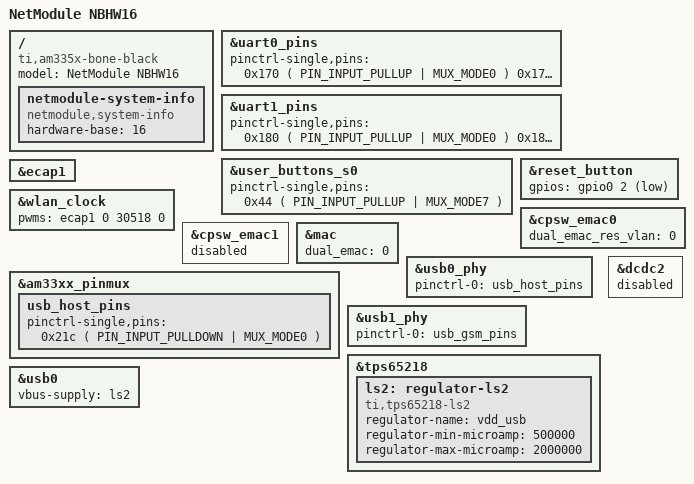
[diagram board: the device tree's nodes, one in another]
/*
 * Copyright (C) 2012 Texas Instruments Incorporated - http://www.ti.com/
 *
 * This program is free software; you can redistribute it and/or modify
 * it under the terms of the GNU General Public License version 2 as
 * published by the Free Software Foundation.
 */
/dts-v1/;

#include "am33xx.dtsi"
#include "am335x-nbhw-common.dtsi"

/ {
	model = "NetModule NBHW16";
	compatible = "ti,am335x-bone-black", "ti,am335x-bone", "ti,am33xx";

	netmodule-system-info {
		compatible = "netmodule,system-info";
		hardware-base = <16>;
	};
};

&uart0_pins {
	pinctrl-single,pins = <
		0x170 ( PIN_INPUT_PULLUP | MUX_MODE0 ) /* (E15) uart0_rxd.uart0_rxd */
		0x174 ( PIN_OUTPUT_PULLUP | MUX_MODE0 ) /* (E16) uart0_txd.uart0_txd */
		0x168 ( PIN_OUTPUT_PULLUP | MUX_MODE0 ) /* (E18) uart0_ctsn.uart0_ctsn */
		0x16C ( PIN_OUTPUT_PULLUP | MUX_MODE0 ) /* (E17) uart0_rtsn.uart0_rtsn */
	>;
};

&uart1_pins {
	pinctrl-single,pins = <
		0x180 ( PIN_INPUT_PULLUP | MUX_MODE0 ) /* (D16) uart1_rxd.uart1_rxd */
		0x184 ( PIN_OUTPUT_PULLUP | MUX_MODE0 ) /* (D15) uart1_txd.uart1_txd */
	>;
};

&user_buttons_s0 {
		pinctrl-single,pins = <
			0x44 ( PIN_INPUT_PULLUP | MUX_MODE7 ) /* (A17) gpmc_a1.gpio0[2] */ /* BUTTON */
		>;
};

&reset_button {
	gpios = <&gpio0 2 GPIO_ACTIVE_LOW>;
};

&ecap1 {
	status = "okay";
};

&wlan_clock {
	pwms = <&ecap1 0 30518 0>;
};

&cpsw_emac0 {
	dual_emac_res_vlan = <0>;
};

// V2 only has one mac
&cpsw_emac1 {
	status = "disabled";
};

&mac {
	dual_emac = <0>;
};

&am33xx_pinmux {
    usb_host_pins: usb_host_pins {
        pinctrl-single,pins = <
            0x21c ( PIN_INPUT_PULLDOWN | MUX_MODE0 ) /* (F16) USB0_DRVVBUS.USB0_DRVVBUS */
        >;
    };
};

&usb0_phy {
	pinctrl-names = "default";
	pinctrl-0 =  <&usb_host_pins>;
	status = "okay";
};

&usb1_phy {
	pinctrl-names = "default";
	pinctrl-0 =  <&usb_gsm_pins>;
	status = "okay";
};

&tps65218 {
    ls2: regulator-ls2 {
 			compatible = "ti,tps65218-ls2";
			regulator-name = "vdd_usb";
            regulator-min-microamp = <500000>;
            regulator-max-microamp = <2000000>;
    };
};

&dcdc2 {
    status = "disabled";
};

&usb0 {
    vbus-supply = <&ls2>;
};
